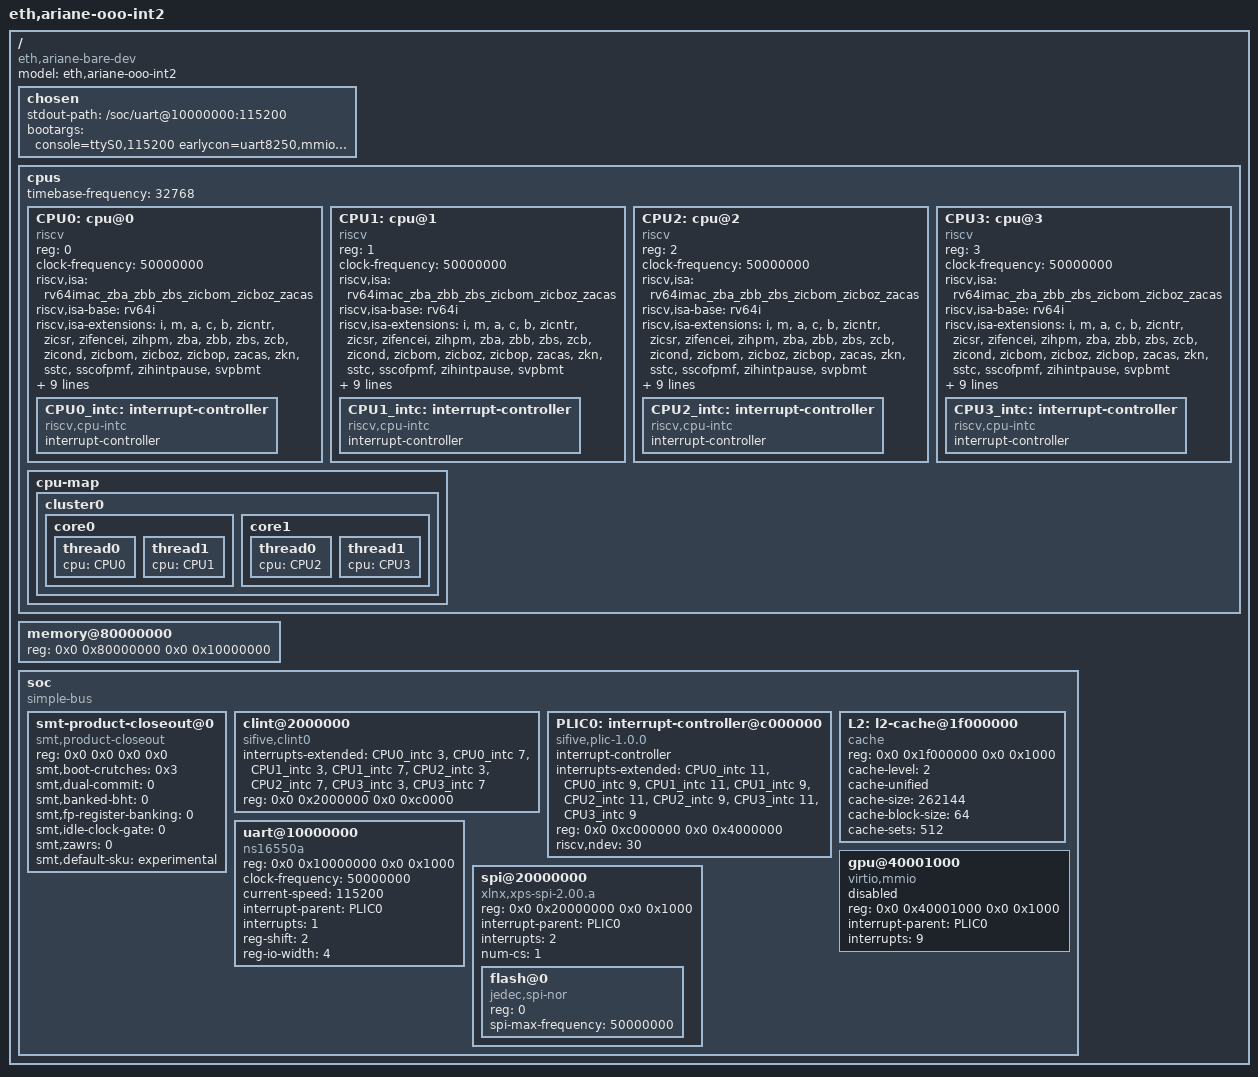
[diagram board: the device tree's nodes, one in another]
// SPDX-License-Identifier: CERN-OHL-S-2.0 OR LicenseRef-GSys-Commercial
// Copyright (c) 2026 Etienne Cimon
//
// Two-core SMT2 integer OoO DTS for g6lc64_ooo_int2_config_pkg
// (NrCores=2, NrHarts=2, CohPolicy=COH_OOO, L2En=1, L3En=0, RVF/RVD=0).
//
// Shape is taken only from the sparse Linux tree (fetch-linux-dts.ps1):
//   «dts»/Documentation/devicetree/bindings/riscv/cpus.yaml  (hart = execution context)
//   «dts»/Documentation/devicetree/bindings/riscv/extensions.yaml
//   «dts»/Documentation/devicetree/bindings/timer/sifive,clint.yaml
//   «dts»/Documentation/devicetree/bindings/interrupt-controller/sifive,plic-1.0.0.yaml
//   «dts»/arch/riscv/boot/dts/sifive/fu540-c000.dtsi       (cpu + cpu-map + plic list form)
//   «dts»/arch/riscv/boot/dts/microchip/mpfs.dtsi           (clint multi-hart list form)
//
// Topology (cpus.yaml): two physical cores, two SMT threads each →
// cpu-map core0{thread0,thread1} core1{thread0,thread1}. mhartid = core*NrHarts + thread
// (g6lc_cluster hart_id_base), matching CSR bank, CLINT and PLIC slot indices.
//
// ISA: the integer package. No f/d (FpPresent=0), otherwise the ariane-smt2.dts
// set; zawrs stays unadvertised for the same SMT closeout reason (no wait-for-peer wake).
//
// Validate: .\build-platform\scripts\validate-cva6-dts.ps1 and
//   python software/smt2-linux/scripts/dts_to_dtb.py -i corev_apu/bootrom/ariane-ooo-int2.dts -o <dtb>
// Unfixable gaps (no Linux vendor enum, no chip CLINT/PLIC ID): dts-linux-smt.md §3.2

/dts-v1/;

/ {
  #address-cells = <2>;
  #size-cells = <2>;
  // Board-level model only — not a cpus.yaml vendor CPU ID
  compatible = "eth,ariane-bare-dev";
  model = "eth,ariane-ooo-int2";

  chosen {
    stdout-path = "/soc/uart@10000000:115200";
    bootargs = "console=ttyS0,115200 earlycon=uart8250,mmio,0x10000000,115200n8 maxcpus=4 root=/dev/ram rw";
  };

  cpus {
    #address-cells = <1>;
    #size-cells = <0>;
    // CLINT timebase (sifive,clint.yaml → /cpus timebase-frequency)
    timebase-frequency = <32768>;

    CPU0: cpu@0 {
      device_type = "cpu";
      compatible = "riscv";
      reg = <0>;
      status = "okay";
      clock-frequency = <50000000>;
      // Integer OoO package: rv64imac + Zacas + Zicbo* + bitmanip; no F/D, no RVV.
      riscv,isa = "rv64imac_zba_zbb_zbs_zicbom_zicboz_zacas";
      riscv,isa-base = "rv64i";
      // Tokens only from extensions.yaml; set matches g6lc64_ooo_int2_config_pkg
      riscv,isa-extensions = "i", "m", "a", "c", "b",
        "zicntr", "zicsr", "zifencei", "zihpm",
        "zba", "zbb", "zbs",
        "zcb", "zicond",
        "zicbom", "zicboz", "zicbop",
        "zacas",
        "zkn",
        "sstc", "sscofpmf", "zihintpause", "svpbmt";
      mmu-type = "riscv,sv39";
      tlb-split;
      riscv,cboz-block-size = <64>;
      riscv,cbom-block-size = <64>;
      // L1 truth: IcacheLineWidth/DcacheLineWidth = 128 bit → 16 B
      i-cache-block-size = <16>;
      i-cache-size = <16384>;
      d-cache-block-size = <16>;
      d-cache-size = <32768>;
      next-level-cache = <&L2>;

      CPU0_intc: interrupt-controller {
        #interrupt-cells = <1>;
        interrupt-controller;
        compatible = "riscv,cpu-intc";
      };
    };

    CPU1: cpu@1 {
      device_type = "cpu";
      compatible = "riscv";
      reg = <1>;
      status = "okay";
      clock-frequency = <50000000>;
      riscv,isa = "rv64imac_zba_zbb_zbs_zicbom_zicboz_zacas";
      riscv,isa-base = "rv64i";
      riscv,isa-extensions = "i", "m", "a", "c", "b",
        "zicntr", "zicsr", "zifencei", "zihpm",
        "zba", "zbb", "zbs",
        "zcb", "zicond",
        "zicbom", "zicboz", "zicbop",
        "zacas",
        "zkn",
        "sstc", "sscofpmf", "zihintpause", "svpbmt";
      mmu-type = "riscv,sv39";
      tlb-split;
      riscv,cboz-block-size = <64>;
      riscv,cbom-block-size = <64>;
      i-cache-block-size = <16>;
      i-cache-size = <16384>;
      d-cache-block-size = <16>;
      d-cache-size = <32768>;
      next-level-cache = <&L2>;

      CPU1_intc: interrupt-controller {
        #interrupt-cells = <1>;
        interrupt-controller;
        compatible = "riscv,cpu-intc";
      };
    };

    CPU2: cpu@2 {
      device_type = "cpu";
      compatible = "riscv";
      reg = <2>;
      status = "okay";
      clock-frequency = <50000000>;
      riscv,isa = "rv64imac_zba_zbb_zbs_zicbom_zicboz_zacas";
      riscv,isa-base = "rv64i";
      riscv,isa-extensions = "i", "m", "a", "c", "b",
        "zicntr", "zicsr", "zifencei", "zihpm",
        "zba", "zbb", "zbs",
        "zcb", "zicond",
        "zicbom", "zicboz", "zicbop",
        "zacas",
        "zkn",
        "sstc", "sscofpmf", "zihintpause", "svpbmt";
      mmu-type = "riscv,sv39";
      tlb-split;
      riscv,cboz-block-size = <64>;
      riscv,cbom-block-size = <64>;
      i-cache-block-size = <16>;
      i-cache-size = <16384>;
      d-cache-block-size = <16>;
      d-cache-size = <32768>;
      next-level-cache = <&L2>;

      CPU2_intc: interrupt-controller {
        #interrupt-cells = <1>;
        interrupt-controller;
        compatible = "riscv,cpu-intc";
      };
    };

    CPU3: cpu@3 {
      device_type = "cpu";
      compatible = "riscv";
      reg = <3>;
      status = "okay";
      clock-frequency = <50000000>;
      riscv,isa = "rv64imac_zba_zbb_zbs_zicbom_zicboz_zacas";
      riscv,isa-base = "rv64i";
      riscv,isa-extensions = "i", "m", "a", "c", "b",
        "zicntr", "zicsr", "zifencei", "zihpm",
        "zba", "zbb", "zbs",
        "zcb", "zicond",
        "zicbom", "zicboz", "zicbop",
        "zacas",
        "zkn",
        "sstc", "sscofpmf", "zihintpause", "svpbmt";
      mmu-type = "riscv,sv39";
      tlb-split;
      riscv,cboz-block-size = <64>;
      riscv,cbom-block-size = <64>;
      i-cache-block-size = <16>;
      i-cache-size = <16384>;
      d-cache-block-size = <16>;
      d-cache-size = <32768>;
      next-level-cache = <&L2>;

      CPU3_intc: interrupt-controller {
        #interrupt-cells = <1>;
        interrupt-controller;
        compatible = "riscv,cpu-intc";
      };
    };

    // Two physical cores, two SMT threads (harts) each — cpus.yaml terminology
    cpu-map {
      cluster0 {
        core0 {
          thread0 {
            cpu = <&CPU0>;
          };
          thread1 {
            cpu = <&CPU1>;
          };
        };
        core1 {
          thread0 {
            cpu = <&CPU2>;
          };
          thread1 {
            cpu = <&CPU3>;
          };
        };
      };
    };
  };

  // Sim-friendly 256 MiB (matches the testharness DRAM window used by the
  // isolated two-core route). Board overlays may extend the size.
  memory@80000000 {
    device_type = "memory";
    reg = <0x0 0x80000000 0x0 0x10000000>;
  };

  soc {
    #address-cells = <2>;
    #size-cells = <2>;
    compatible = "simple-bus";
    ranges;

    // SMT2 product-closeout checklist — DOCUMENTATION ONLY (same core as
    // ariane-smt2.dts; see that file and smt2-product-closeout.md).
    // dts_to_dtb.py fails the build if a cpu@ advertises a token listed absent.
    smt-product-closeout@0 {
      compatible = "smt,product-closeout";
      reg = <0x0 0x0 0x0 0x0>;
      smt,boot-crutches = <0x3>;          /* SMT_COLD_EXCL | SMT_FIRST_ACT_EXCL */
      smt,dual-commit = <0>;              /* two harts cannot commit CSRs same cycle */
      smt,banked-bht = <0>;               /* BHT/BTB shared across harts */
      smt,fp-register-banking = <0>;      /* no F/D on this package */
      smt,idle-clock-gate = <0>;          /* secondary cores are boot-held, not idle-gated */
      smt,zawrs = <0>;                    /* no wait-for-peer wake */
      smt,default-sku = "experimental";   /* two-core SMT2 OoO not yet a production default SKU */
    };

    // 4 harts × (MSIP=3, MTIP=7) — mpfs/fu540 multi-hart list form; slot order is mhartid
    clint@2000000 {
      compatible = "sifive,clint0", "riscv,clint0";
      interrupts-extended =
        <&CPU0_intc 3>, <&CPU0_intc 7>,
        <&CPU1_intc 3>, <&CPU1_intc 7>,
        <&CPU2_intc 3>, <&CPU2_intc 7>,
        <&CPU3_intc 3>, <&CPU3_intc 7>;
      reg = <0x0 0x2000000 0x0 0xc0000>;
    };

    // 4 harts × (M-ext=11, S-ext=9) — 8 PLIC contexts
    PLIC0: interrupt-controller@c000000 {
      compatible = "sifive,plic-1.0.0", "riscv,plic0";
      #address-cells = <0>;
      #interrupt-cells = <1>;
      interrupt-controller;
      interrupts-extended =
        <&CPU0_intc 11>, <&CPU0_intc 9>,
        <&CPU1_intc 11>, <&CPU1_intc 9>,
        <&CPU2_intc 11>, <&CPU2_intc 9>,
        <&CPU3_intc 11>, <&CPU3_intc 9>;
      reg = <0x0 0xc000000 0x0 0x4000000>;
      riscv,ndev = <30>;
    };

    // Shared L2 (package L2ByteSize=262144, L2SetAssoc=8, L2LineWidth=512 bit → 64 B, 512 sets).
    // Soft node for the next-level-cache phandle; reserved MMIO hole, not a bus slave.
    L2: l2-cache@1f000000 {
      compatible = "cache";
      reg = <0x0 0x1f000000 0x0 0x1000>;
      cache-level = <2>;
      cache-unified;
      cache-size = <262144>;
      cache-block-size = <64>;
      cache-sets = <512>;
    };

    uart@10000000 {
      compatible = "ns16550a";
      reg = <0x0 0x10000000 0x0 0x1000>;
      clock-frequency = <50000000>;
      current-speed = <115200>;
      interrupt-parent = <&PLIC0>;
      interrupts = <1>;
      reg-shift = <2>;
      reg-io-width = <4>;
    };

    // LibreCore APU guest window. status=disabled until testharness
    // instantiates g6lc_apu_soc. PLIC source 9; firmware control at
    // 0x40002000 is omitted so Linux cannot map it.
    gpu@40001000 {
      compatible = "virtio,mmio";
      reg = <0x0 0x40001000 0x0 0x1000>;
      interrupt-parent = <&PLIC0>;
      interrupts = <9>;
      status = "disabled";
    };

    // FPGA xlnx_axi_quad_spi at SPIBase; ip2intc_irpt = irq_sources[1] = PLIC 2.
    spi@20000000 {
      compatible = "xlnx,xps-spi-2.00.a";
      reg = <0x0 0x20000000 0x0 0x1000>;
      interrupt-parent = <&PLIC0>;
      interrupts = <2>;
      #address-cells = <1>;
      #size-cells = <0>;
      num-cs = <1>;
      flash@0 {
        compatible = "jedec,spi-nor";
        reg = <0>;
        spi-max-frequency = <50000000>;
      };
    };
  };
};
